AUTOSAR XML (schema 00051)
package /Components
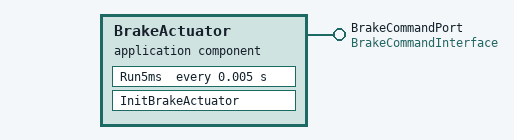
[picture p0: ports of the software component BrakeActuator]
  application sw component type BrakeActuator
    provide port BrakeCommandPort: provided-interface=BrakeCommandInterface
    behavior BrakeActuator_IB
      timing event TE_Run5ms: start-on-event=Run5ms, period=0.005
      init event IE_InitBrakeActuator: start-on-event=InitBrakeActuator
      runnable Run5ms
        data-write-access:
          access VA_Run5ms_BrakeCommandPort: accessed-variable=BrakeCommandPort.BrakeTorque
      runnable InitBrakeActuator
